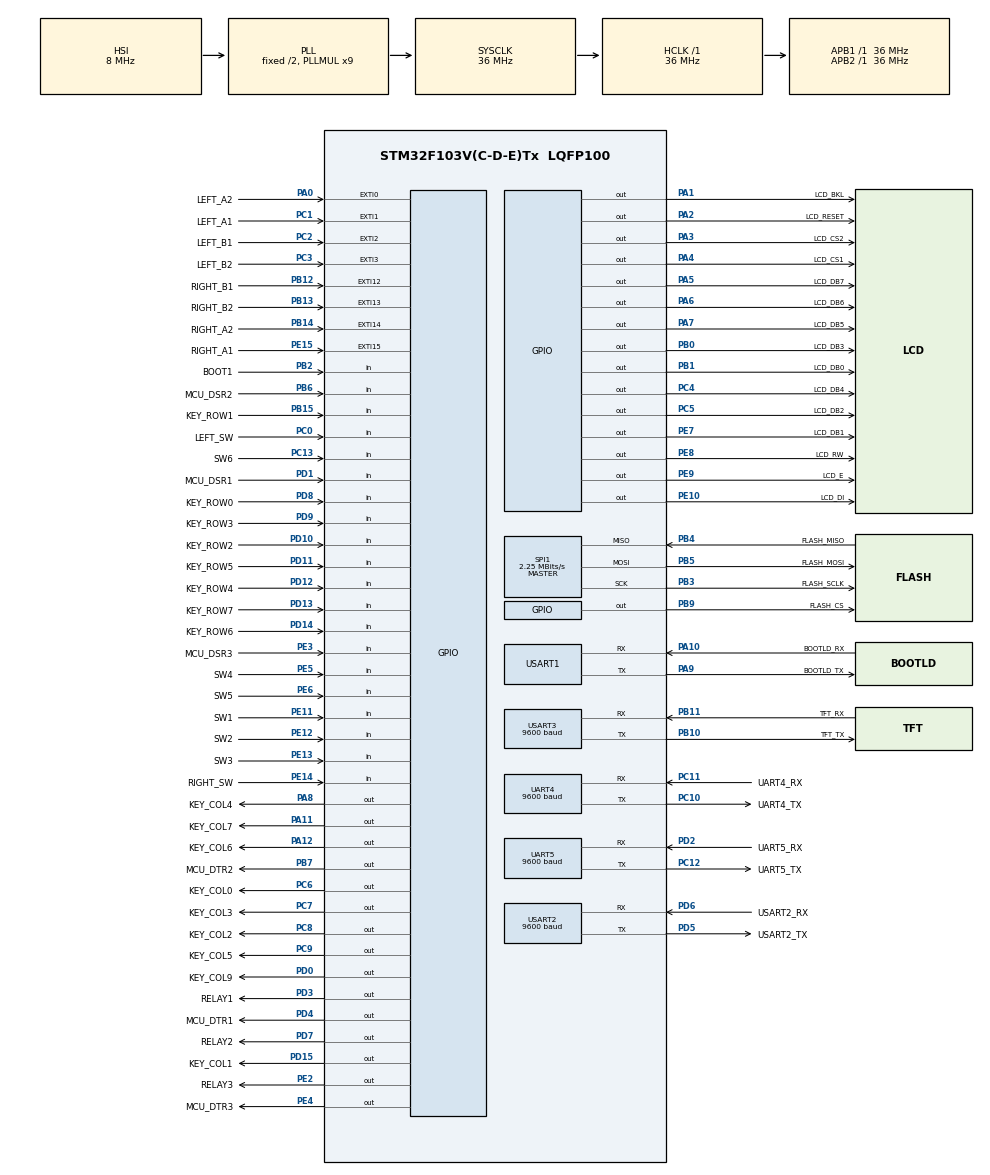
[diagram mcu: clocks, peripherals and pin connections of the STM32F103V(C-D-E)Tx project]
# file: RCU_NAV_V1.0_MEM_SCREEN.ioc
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FREERTOS.Tasks01=defaultTask,24,128,StartDefaultTask,Default,NULL,Dynamic,NULL,NULL
FREERTOS.configTOTAL_HEAP_SIZE=15000
FREERTOS.configUSE_NEWLIB_REENTRANT=1
Mcu.Family=STM32F1
Mcu.Name=STM32F103V(C-D-E)Tx
Mcu.Package=LQFP100
NVIC.EXTI0_IRQn=true\:5\:0\:true\:false\:true\:true\:true\:true\:true
NVIC.EXTI15_10_IRQn=true\:5\:0\:false\:false\:true\:true\:true\:true\:true
NVIC.EXTI1_IRQn=true\:5\:0\:false\:false\:true\:true\:true\:true\:true
NVIC.EXTI2_IRQn=true\:5\:0\:false\:false\:true\:true\:true\:true\:true
NVIC.EXTI3_IRQn=true\:5\:0\:false\:false\:true\:true\:true\:true\:true
NVIC.PriorityGroup=NVIC_PRIORITYGROUP_4
NVIC.TIM6_IRQn=true\:15\:0\:false\:false\:true\:false\:false\:true\:true
NVIC.TimeBase=TIM6_IRQn
NVIC.TimeBaseIP=TIM6
NVIC.UART4_IRQn=true\:8\:0\:true\:false\:true\:true\:true\:true\:true
NVIC.UART5_IRQn=true\:8\:0\:true\:false\:true\:true\:true\:true\:true
PA0-WKUP.GPIO_Label=LEFT_A2
PA0-WKUP.Signal=GPXTI0
PA1.GPIO_Label=LCD_BKL
PA1.Signal=GPIO_Output
PA10.GPIO_Label=BOOTLD_RX
PA10.Mode=Asynchronous
PA10.Signal=USART1_RX
PA11.GPIO_Label=KEY_COL7
PA11.Signal=GPIO_Output
PA12.GPIO_Label=KEY_COL6
PA12.Signal=GPIO_Output
PA13.Mode=Serial_Wire
PA13.Signal=SYS_JTMS-SWDIO
PA14.Mode=Serial_Wire
PA14.Signal=SYS_JTCK-SWCLK
PA2.GPIO_Label=LCD_RESET
PA2.Signal=GPIO_Output
PA3.GPIO_Label=LCD_CS2
PA3.Signal=GPIO_Output
PA4.GPIO_Label=LCD_CS1
PA4.Signal=GPIO_Output
PA5.GPIO_Label=LCD_DB7
PA5.Signal=GPIO_Output
PA6.GPIO_Label=LCD_DB6
PA6.Signal=GPIO_Output
PA7.GPIO_Label=LCD_DB5
PA7.Signal=GPIO_Output
PA8.GPIO_Label=KEY_COL4
PA8.Signal=GPIO_Output
PA9.GPIO_Label=BOOTLD_TX
PA9.Mode=Asynchronous
PA9.Signal=USART1_TX
PB0.GPIO_Label=LCD_DB3
PB0.Signal=GPIO_Output
PB1.GPIO_Label=LCD_DB0
PB1.Signal=GPIO_Output
PB10.GPIO_Label=TFT_TX
PB10.Mode=Asynchronous
PB10.Signal=USART3_TX
PB11.GPIO_Label=TFT_RX
PB11.Mode=Asynchronous
PB11.Signal=USART3_RX
PB12.GPIO_Label=RIGHT_B1
PB12.Signal=GPXTI12
PB13.GPIO_Label=RIGHT_B2
PB13.Signal=GPXTI13
PB14.GPIO_Label=RIGHT_A2
PB14.Signal=GPXTI14
PB15.GPIO_Label=KEY_ROW1
PB15.Signal=GPIO_Input
PB2.GPIO_Label=BOOT1
PB2.Signal=GPIO_Input
PB3.GPIO_Label=FLASH_SCLK
PB3.Mode=Full_Duplex_Master
PB3.Signal=SPI1_SCK
PB4.GPIO_Label=FLASH_MISO
PB4.Mode=Full_Duplex_Master
PB4.Signal=SPI1_MISO
PB5.GPIO_Label=FLASH_MOSI
PB5.Mode=Full_Duplex_Master
PB5.Signal=SPI1_MOSI
PB6.GPIO_Label=MCU_DSR2
PB6.Signal=GPIO_Input
PB7.GPIO_Label=MCU_DTR2
PB7.Signal=GPIO_Output
PB9.GPIO_Label=FLASH_CS
PB9.Signal=GPIO_Output
PC0.GPIO_Label=LEFT_SW
PC0.Signal=GPIO_Input
PC1.GPIO_Label=LEFT_A1
PC1.Signal=GPXTI1
PC10.GPIO_Label=UART4_TX
PC10.Mode=Asynchronous
PC10.Signal=UART4_TX
PC11.GPIO_Label=UART4_RX
PC11.Mode=Asynchronous
PC11.Signal=UART4_RX
PC12.GPIO_Label=UART5_TX
PC12.Mode=Asynchronous
PC12.Signal=UART5_TX
PC13-TAMPER-RTC.GPIO_Label=SW6
PC13-TAMPER-RTC.Signal=GPIO_Input
PC2.GPIO_Label=LEFT_B1
PC2.Signal=GPXTI2
PC3.GPIO_Label=LEFT_B2
PC3.Signal=GPXTI3
PC4.GPIO_Label=LCD_DB4
PC4.Signal=GPIO_Output
PC5.GPIO_Label=LCD_DB2
PC5.Signal=GPIO_Output
PC6.GPIO_Label=KEY_COL0
PC6.Signal=GPIO_Output
PC7.GPIO_Label=KEY_COL3
PC7.Signal=GPIO_Output
PC8.GPIO_Label=KEY_COL2
PC8.Signal=GPIO_Output
PC9.GPIO_Label=KEY_COL5
PC9.Signal=GPIO_Output
PD0.GPIO_Label=KEY_COL9
PD0.Signal=GPIO_Output
PD1.GPIO_Label=MCU_DSR1
PD1.Signal=GPIO_Input
PD10.GPIO_Label=KEY_ROW2
PD10.Signal=GPIO_Input
PD11.GPIO_Label=KEY_ROW5
PD11.Signal=GPIO_Input
PD12.GPIO_Label=KEY_ROW4
PD12.Signal=GPIO_Input
PD13.GPIO_Label=KEY_ROW7
PD13.Signal=GPIO_Input
PD14.GPIO_Label=KEY_ROW6
PD14.Signal=GPIO_Input
PD15.GPIO_Label=KEY_COL1
PD15.Signal=GPIO_Output
PD2.GPIO_Label=UART5_RX
PD2.GPIO_PuPd=GPIO_PULLDOWN
PD2.Mode=Asynchronous
PD2.Signal=UART5_RX
PD3.GPIO_Label=RELAY1
PD3.Signal=GPIO_Output
PD4.GPIO_Label=MCU_DTR1
PD4.Signal=GPIO_Output
PD5.GPIO_Label=USART2_TX
PD5.Mode=Asynchronous
PD5.Signal=USART2_TX
PD6.GPIO_Label=USART2_RX
PD6.Mode=Asynchronous
PD6.Signal=USART2_RX
PD7.GPIO_Label=RELAY2
PD7.Signal=GPIO_Output
PD8.GPIO_Label=KEY_ROW0
PD8.Signal=GPIO_Input
PD9.GPIO_Label=KEY_ROW3
PD9.Signal=GPIO_Input
PE10.GPIO_Label=LCD_DI
PE10.Signal=GPIO_Output
PE11.GPIO_Label=SW1
PE11.Signal=GPIO_Input
PE12.GPIO_Label=SW2
PE12.Signal=GPIO_Input
PE13.GPIO_Label=SW3
PE13.Signal=GPIO_Input
PE14.GPIO_Label=RIGHT_SW
PE14.Signal=GPIO_Input
PE15.GPIO_Label=RIGHT_A1
PE15.Signal=GPXTI15
PE2.GPIO_Label=RELAY3
PE2.Signal=GPIO_Output
PE3.GPIO_Label=MCU_DSR3
PE3.Signal=GPIO_Input
PE4.GPIO_Label=MCU_DTR3
PE4.Signal=GPIO_Output
PE5.GPIO_Label=SW4
PE5.Signal=GPIO_Input
PE6.GPIO_Label=SW5
PE6.Signal=GPIO_Input
PE7.GPIO_Label=LCD_DB1
PE7.Signal=GPIO_Output
PE8.GPIO_Label=LCD_RW
PE8.Signal=GPIO_Output
PE9.GPIO_Label=LCD_E
PE9.Signal=GPIO_Output
ProjectManager.HeapSize=0x200
ProjectManager.StackSize=0x400
ProjectManager.TargetToolchain=STM32CubeIDE
RCC.AHBFreq_Value=36000000
RCC.APB1Freq_Value=36000000
RCC.APB1TimFreq_Value=36000000
RCC.APB2Freq_Value=36000000
RCC.APB2TimFreq_Value=36000000
RCC.HCLKFreq_Value=36000000
RCC.PLLMUL=RCC_PLL_MUL9
RCC.SYSCLKFreq_VALUE=36000000
RCC.SYSCLKSource=RCC_SYSCLKSOURCE_PLLCLK
RCC.USBFreq_Value=36000000
SPI1.BaudRatePrescaler=SPI_BAUDRATEPRESCALER_16
SPI1.CalculateBaudRate=2.25 MBits/s
SPI1.Direction=SPI_DIRECTION_2LINES
SPI1.Mode=SPI_MODE_MASTER
SPI1.VirtualType=VM_MASTER
UART4.BaudRate=9600
UART4.VirtualMode=Asynchronous
UART5.BaudRate=9600
UART5.VirtualMode=Asynchronous
USART1.VirtualMode=VM_ASYNC
USART2.BaudRate=9600
USART2.VirtualMode=VM_ASYNC
USART3.BaudRate=9600
USART3.VirtualMode=VM_ASYNC
VP_FREERTOS_VS_CMSIS_V2.Mode=CMSIS_V2
VP_SYS_VS_tim6.Mode=TIM6
board=custom

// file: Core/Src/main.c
/* USER CODE BEGIN Header */
/**
  ******************************************************************************
  * @file           : main.c
  * @brief          : Main program body
  ******************************************************************************
  * @attention
  *
  * Copyright (c) 2024 STMicroelectronics.
  * All rights reserved.
  *
  * This software is licensed under terms that can be found in the LICENSE file
  * in the root directory of this software component.
  * If no LICENSE file comes with this software, it is provided AS-IS.
  *
  ******************************************************************************
  */
#define FREERTOS
/* USER CODE END Header */
#include "main.h"
#include "cmsis_os.h"
#include "spi.h"
#include "usart.h"
#include "gpio.h"

/* USER CODE BEGIN Includes */
#include "glcd.h"
/* USER CODE END Includes */

void SystemClock_Config(void);
void MX_FREERTOS_Init(void);

int main(void)
{

  /* MCU Configuration--------------------------------------------------------*/

  /* Reset of all peripherals, Initializes the Flash interface and the Systick. */
  HAL_Init();

  /* Configure the system clock */
  SystemClock_Config();

  /* Initialize all configured peripherals */
  MX_GPIO_Init();
  MX_SPI1_Init();
  MX_UART4_Init();
  MX_UART5_Init();
  MX_USART1_UART_Init();
  MX_USART2_UART_Init();
  MX_USART3_UART_Init();
  /* USER CODE BEGIN 2 */
  NVIC_SetPriorityGrouping( NVIC_PRIORITYGROUP_4 );

#ifndef FREERTOS
  /* USER CODE END 2 */

  /* Init scheduler */
  osKernelInitialize();

  /* Call init function for freertos objects (in cmsis_os2.c) */
  MX_FREERTOS_Init();

  /* Start scheduler */
  osKernelStart();

  /* We should never get here as control is now taken by the scheduler */

  /* Infinite loop */
  /* USER CODE BEGIN WHILE */
#else
  /* Call initialize function for free-rtos objects (in cmsis_os2.c) */
  MX_FREERTOS_Init();
#endif
  while (1)
  {
    /* USER CODE END WHILE */

  }
}

void SystemClock_Config(void)
{
  RCC_OscInitTypeDef RCC_OscInitStruct = {0};
  RCC_ClkInitTypeDef RCC_ClkInitStruct = {0};

  /** Initializes the RCC Oscillators according to the specified parameters
  * in the RCC_OscInitTypeDef structure.
  */
  RCC_OscInitStruct.OscillatorType = RCC_OSCILLATORTYPE_HSI;
  RCC_OscInitStruct.HSIState = RCC_HSI_ON;
  RCC_OscInitStruct.HSICalibrationValue = RCC_HSICALIBRATION_DEFAULT;
  RCC_OscInitStruct.PLL.PLLState = RCC_PLL_ON;
  RCC_OscInitStruct.PLL.PLLSource = RCC_PLLSOURCE_HSI_DIV2;
  RCC_OscInitStruct.PLL.PLLMUL = RCC_PLL_MUL9;
  if (HAL_RCC_OscConfig(&RCC_OscInitStruct) != HAL_OK)
  {
    Error_Handler();
  }

  /** Initializes the CPU, AHB and APB buses clocks
  */
  RCC_ClkInitStruct.ClockType = RCC_CLOCKTYPE_HCLK|RCC_CLOCKTYPE_SYSCLK
                              |RCC_CLOCKTYPE_PCLK1|RCC_CLOCKTYPE_PCLK2;
  RCC_ClkInitStruct.SYSCLKSource = RCC_SYSCLKSOURCE_PLLCLK;
  RCC_ClkInitStruct.AHBCLKDivider = RCC_SYSCLK_DIV1;
  RCC_ClkInitStruct.APB1CLKDivider = RCC_HCLK_DIV1;
  RCC_ClkInitStruct.APB2CLKDivider = RCC_HCLK_DIV1;

  if (HAL_RCC_ClockConfig(&RCC_ClkInitStruct, FLASH_LATENCY_1) != HAL_OK)
  {
    Error_Handler();
  }
}

void HAL_TIM_PeriodElapsedCallback(TIM_HandleTypeDef *htim)
{
  if (htim->Instance == TIM6) {
    HAL_IncTick();
  }
}

void Error_Handler(void)
{
  __disable_irq();
  while (1)
  {
  }
}

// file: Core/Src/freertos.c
/* USER CODE BEGIN Header */
/**
 ******************************************************************************
 * File Name          : freertos.c
 * Description        : Code for freertos applications
 ******************************************************************************
 * @attention
 *
 * Copyright (c) 2024 STMicroelectronics.
 * All rights reserved.
 *
 * This software is licensed under terms that can be found in the LICENSE file
 * in the root directory of this software component.
 * If no LICENSE file comes with this software, it is provided AS-IS.
 *
 ******************************************************************************
 */
#define FREERTOS
#ifndef FREERTOS
/* USER CODE END Header */

#include "FreeRTOS.h"
#include "task.h"
#include "main.h"
#include "cmsis_os.h"

/* Definitions for defaultTask */
osThreadId_t defaultTaskHandle;
const osThreadAttr_t defaultTask_attributes = {
  .name = "defaultTask",
  .stack_size = 128 * 4,
  .priority = (osPriority_t) osPriorityNormal,
};

void StartDefaultTask(void *argument);

void MX_FREERTOS_Init(void); /* (MISRA C 2004 rule 8.1) */

void MX_FREERTOS_Init(void) {

  /* Create the thread(s) */
  /* creation of defaultTask */
  defaultTaskHandle = osThreadNew(StartDefaultTask, NULL, &defaultTask_attributes);

}

void StartDefaultTask(void *argument)
{
    for (;;)
    {
        osDelay(1);
    }
}

/* USER CODE BEGIN Application */
#else

/* ---------------------------------- Includes --------------------------------
 */
#include "FreeRTOS.h"
#include "data_handler.h"
#include "debug_console.h"
#include "event_groups.h"
#include "main.h"
#include "queue.h"
#include "serial_handler.h"
#include "task.h"

/* ----------------------------------- MACROS
 * ----------------------------------- */

#define CDU_COM_STACK_SIZE 256
#define NAV_RECEIVER_COM_STACK_SIZE 256
#define DATA_HANDLER_STACK_SIZE 1024
#define USER_INPUTS_STACK_SIZE 128
#if DEBUG_CONSOLE
#define DEBUG_CONSOLE_STACK_SIZE 2096
#endif

/* ----------------------------------- Queue Handles
 * ----------------------------- */
xQueueHandle xCDUCOMRxQueue = NULL;
xQueueHandle xCDUCOMTxQueue = NULL;
xQueueHandle xNAVRecRxQueue = NULL;
xQueueHandle xNAVRecTxQueue = NULL;
xQueueHandle xMainNotifyQueue = NULL;
#if DEBUG_CONSOLE
xQueueHandle xDebugQueue = NULL;
#endif

/* ----------------------------------- Event group
 * ------------------------------- */
EventGroupHandle_t buttonEventGroup;

/* ----------------------------------- Functions
 * --------------------------------- */

void create_NAV_RCU_Tasks(void)
{
    xTaskCreate(serial_CDU_com_thread, "CDU Communication", CDU_COM_STACK_SIZE, (void *)1, 10, NULL);
    xTaskCreate(serial_NAV_Receiver_com_thread, "NAV Receiver Communication", NAV_RECEIVER_COM_STACK_SIZE, (void *)1,
                10, NULL);
    xTaskCreate(general_purpose_switches_thread, " Switches Polling ", USER_INPUTS_STACK_SIZE, (void *)1, 10, NULL);
    xTaskCreate(NAV_RCU_main_thread, "Main", DATA_HANDLER_STACK_SIZE, (void *)1, 10, NULL);

#if DEBUG_CONSOLE
    xTaskCreate(debug_console_thread, "Debug Console", DEBUG_CONSOLE_STACK_SIZE, (void *)1, 5, NULL);
#endif
}

void create_NAV_RCU_Queues(void)
{
    xCDUCOMRxQueue = xQueueCreate(10, sizeof(char[25]));
#if DEBUG_CONSOLE
    if (xCDUCOMRxQueue == NULL)
    {
        debug_print("Error: Failed to Create Queue. xCDUCOMRxQueue \r\n");
    }
#endif

    xCDUCOMTxQueue = xQueueCreate(10, sizeof(Identifier));
#if DEBUG_CONSOLE
    if (xCDUCOMTxQueue == NULL)
    {
        debug_print("Error: Failed to Create Queue. xCDUCOMTxQueue \r\n");
    }
#endif

    xNAVRecRxQueue = xQueueCreate(10, sizeof(char[25]));
#if DEBUG_CONSOLE
    if (xNAVRecRxQueue == NULL)
    {
        debug_print("Error: Failed to Create Queue. xNAVRecRxQueue \r\n");
    }
#endif

    xNAVRecTxQueue = xQueueCreate(10, sizeof(s_NAV_RCU_Parameters));
#if DEBUG_CONSOLE
    if (xNAVRecTxQueue == NULL)
    {
        debug_print("Error: Failed to Create Queue. xNAVRecTxQueue \r\n");
    }
#endif

    xMainNotifyQueue = xQueueCreate(10, sizeof(Identifier));
#if DEBUG_CONSOLE
    if (xMainNotifyQueue == NULL)
    {
        debug_print("Error: Failed to Create Queue. xMainNotifyQueue \r\n");
    }
#endif

#if DEBUG_CONSOLE
    xDebugQueue = xQueueCreate(10, sizeof(char[100]));
    if (xDebugQueue == NULL)
    {
        debug_print("Error: Failed to Create Queue xDebugQueue. \r\n");
    }
#endif
}

void MX_FREERTOS_Init(void)
{
    // Create NAV-RCU Tasks
    create_NAV_RCU_Tasks();

    // Create Queues for user Inputs and Data Transmission/Reception
    create_NAV_RCU_Queues();

    // Create the event group
    buttonEventGroup = xEventGroupCreate();

    // start the scheduler
    vTaskStartScheduler();
}

#endif
/* USER CODE END Application */
